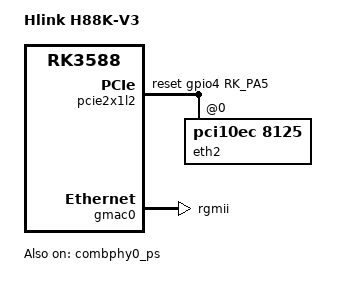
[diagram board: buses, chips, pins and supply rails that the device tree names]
// SPDX-License-Identifier: (GPL-2.0+ OR MIT)
// Copyright (c) 2023 Flippy <flippy@sina.com>

/dts-v1/;

#include "rk3588-hlink.dtsi"

/ {
	model = "Hlink H88K-V3";
	compatible = "hlink,h88k", "rockchip,rk3588";
};

/* rtl8125b 2.5g ethernet */
&pcie2x1l2 {
	reset-gpios = <&gpio4 RK_PA5 GPIO_ACTIVE_HIGH>;
	status = "okay";

	pcie@0,0 {
		reg = <0x00400000 0 0 0 0>;
		#address-cells = <3>;
		#size-cells = <2>;

		rtl8125_2: pcie-eth@0,0 {
			compatible = "pci10ec,8125";
			label = "eth2";
			reg = <0x000000 0 0 0 0>;

			/* G+ 3v3
			 * G- LED3: LINK on 100 + 1000 + 2500
			 * Y+ 3v3
			 * Y- LED2: ACT on all speed
			 */
			r8125,led2 = <0x0200>;
			r8125,led3 = <0x002a>;
		};
	};
};

&combphy0_ps {
	status = "okay";
};

&sdmmc {
	max-frequency = <200000000>;
	sd-uhs-sdr104;
};

&gmac0 {
	phy-mode = "rgmii";
	tx_delay = <0x42>;
	rx_delay = <0x34>;
};
